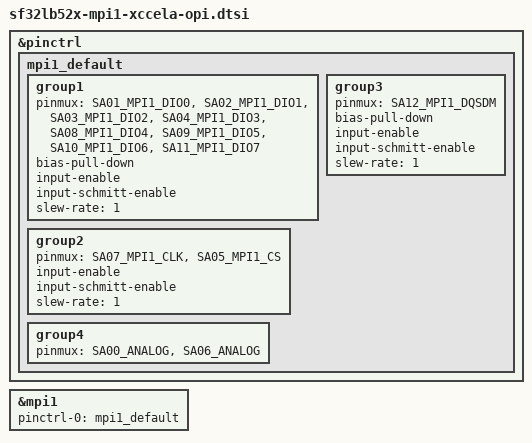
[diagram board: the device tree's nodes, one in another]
/*
 * Copyright (c) 2025 Core Devices LLC
 * Copyright (c) 2025 SiFli Technologies(Nanjing) Co., Ltd
 * SPDX-License-Identifier: Apache-2.0
 */

#include <zephyr/dt-bindings/pinctrl/sf32lb52x-pinctrl.h>

/*
 * MPI1 SiP Xccela OPI PSRAM pinmux (SDK func1, APS 64P XCELLA).
 * Used by: SF32LB525UC6, SF32LB52GUC6.
 */

&pinctrl {
	mpi1_default: mpi1_default {
		group1 {
			pinmux = <SA01_MPI1_DIO0>, <SA02_MPI1_DIO1>,
				 <SA03_MPI1_DIO2>, <SA04_MPI1_DIO3>,
				 <SA08_MPI1_DIO4>, <SA09_MPI1_DIO5>,
				 <SA10_MPI1_DIO6>, <SA11_MPI1_DIO7>;
			bias-pull-down;
			input-enable;
			input-schmitt-enable;
			slew-rate = <1>;
		};

		group2 {
			pinmux = <SA07_MPI1_CLK>, <SA05_MPI1_CS>;
			input-enable;
			input-schmitt-enable;
			slew-rate = <1>;
		};

		group3 {
			pinmux = <SA12_MPI1_DQSDM>;
			bias-pull-down;
			input-enable;
			input-schmitt-enable;
			slew-rate = <1>;
		};

		/* SA00 and SA06 are power supply pins, configure as analog */
		group4 {
			pinmux = <SA00_ANALOG>, <SA06_ANALOG>;
		};
	};
};

&mpi1 {
	pinctrl-0 = <&mpi1_default>;
	pinctrl-names = "default";
};
